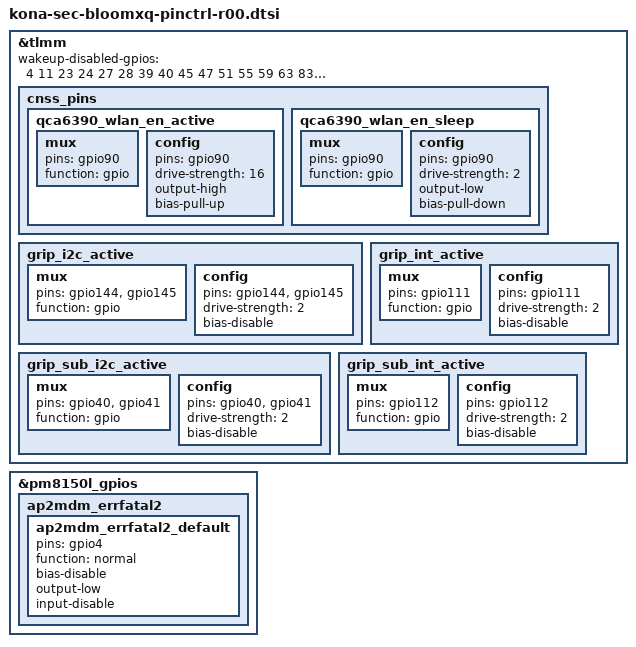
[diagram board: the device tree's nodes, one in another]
/* Copyright (c) 2020, The Linux Foundation. All rights reserved.
 *
 * This program is free software; you can redistribute it and/or modify
 * it under the terms of the GNU General Public License version 2 and
 * only version 2 as published by the Free Software Foundation.
 *
 * This program is distributed in the hope that it will be useful,
 * but WITHOUT ANY WARRANTY; without even the implied warranty of
 * MERCHANTABILITY or FITNESS FOR A PARTICULAR PURPOSE.  See the
 * GNU General Public License for more details.
 */
#include "../drivers/audio_bloomx_pinctrl_common.dtsi"
#include "../drivers/battery_pinctrl_bloomxq_common.dtsi"
#include "../drivers/kona-sec-bloomxq-tsp-pinctrl.dtsi"
#include "../drivers/kona-sec-bloomxq-camera-sensor-pinctrl-r00.dtsi"
#include "../drivers/connector_detection_bloomxq_pinctrl_common.dtsi"

&tlmm {
	cnss_pins {
            qca6390_wlan_en_active: qca6390_wlan_en_active {
                mux {
                    pins = "gpio90";
                    function = "gpio";
                };

                config {
                        pins = "gpio90";
                        drive-strength = <16>;
                        output-high;
                        bias-pull-up;
                };
            };

            qca6390_wlan_en_sleep: qca6390_wlan_en_sleep {
                mux {
                    pins = "gpio90";
                    function = "gpio";
                };

                config {
                    pins = "gpio90";
                    drive-strength = <2>;
                    output-low;
                    bias-pull-down;
                };
            };
    };

	grip_i2c_active: grip_i2c_active {
		mux {
			pins = "gpio144", "gpio145";
			function = "gpio";
		};
		config {
			pins = "gpio144", "gpio145";
			drive-strength = <2>;
			bias-disable;
		};
	};

	grip_int_active: grip_int_active {
		mux {
			pins = "gpio111";
			function = "gpio";
		};
		config {
			pins = "gpio111";
			drive-strength = <2>;
			bias-disable;
		};
	};

	grip_sub_i2c_active: grip_sub_i2c_active {
		mux {
			pins = "gpio40", "gpio41";
			function = "gpio";
		};
		config {
			pins = "gpio40", "gpio41";
			drive-strength = <2>;
			bias-disable;
		};
	};

	grip_sub_int_active: grip_sub_int_active {
		mux {
			pins = "gpio112";
			function = "gpio";
		};
		config {
			pins = "gpio112";
			drive-strength = <2>;
			bias-disable;
		};
	};
};

&pm8150l_gpios {
	ap2mdm_errfatal2 {
		ap2mdm_errfatal2_default: ap2mdm_errfatal2_default {
	        pins = "gpio4";
	        function = "normal";
	        bias-disable;
	        output-low;
	        input-disable;
	    };
	};
};

&tlmm {
	wakeup-disabled-gpios = <
		4	/* I2C : PM3003A_SDA_1P8 */
		11	/* NC : NC */
		23	/* SPI : BTP_SPI_CS_N */
		24	/* NC : NC */
		27	/* NC : NC */
		28	/* I2C : IF_PMIC_SDA_1P8 */
		39	/* NC : NC */
		40	/* I2C : GRIP_MAIN_SDA_1P8 */
		45	/* I2C : NFC_FLICKER_SCL_1P8 */
		47	/* NC : NC */
		51	/* SPI : ESE_SPI_CS_N */
		55	/* NC : NC */
		59	/* NC : NC */
		63	/* I2C : DISP_PMIC_SCL_1P8 */
		83	/* NC : NC */
		100	/* NC : NC */
		103	/* I2C : VT10M_SDA_1P8 */
		104	/* I2C : VT10M_SCL_1P8 */
		108	/* I2C : CAM_AF_EEP_SCL_1P8 */
		113	/* NC : NC */
		118	/* NC : NC */
		121	/* SPI : F_SPI_SCLK */
		122	/* SPI : F_SPI_CSN */
		126	/* I2C : BATT_SCL_1P8 */
		128	/* NC : NC */
		129	/* I2C : MOTOR_SDA_1P8 */
		142	/* SLIMBUS : BT_SLIMBUS_CLK */
		143	/* SLIMBUS : BT_SLIMBUS_DATA */
		147	/* NC : NC */
		150	/* NC : NC */
		160	/* I2C : 6AXIS_I3C_SDA_1P8 */
		162	/* I2C : MAGNETIC_SDA_1P8 */
		164	/* SPI : COPR_MISO */
		166	/* SPI : COPR_SCLK */
		167	/* SPI : COPR_SS */
		175	/* NC : NC */
		177	/* I2C : PROXY_SCL_1P8 */
		179	/* NC : NC */
	>;
};
